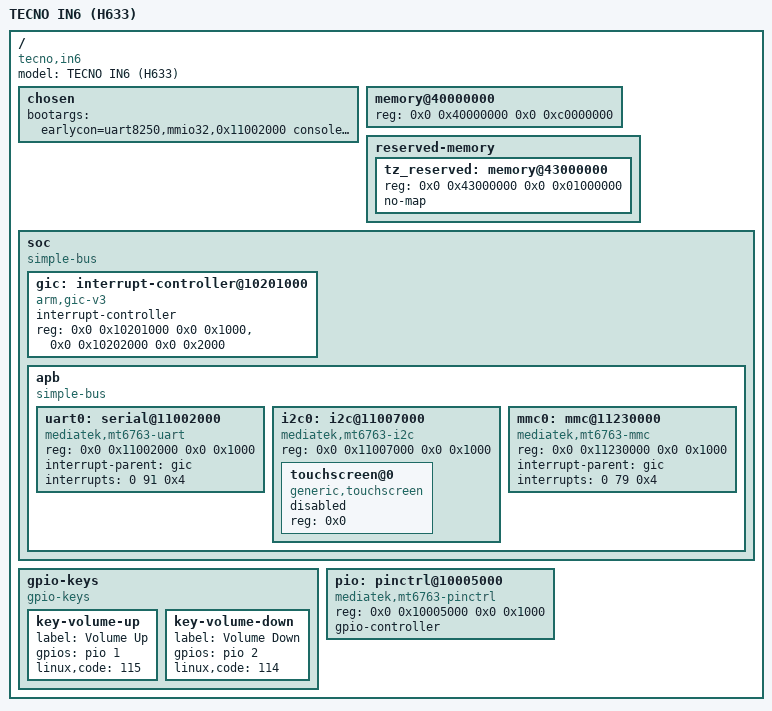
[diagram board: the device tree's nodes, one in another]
// SPDX-License-Identifier: GPL-2.0-only
/*
 * Device Tree Include for TECNO IN6 / H633 (MediaTek MT6763 / Helio P23)
 *
 * Copyright (c) 2025 IN6-Linux Project
 *
 * EVIDENCE TAGGING LEGEND:
 * - CONFIRMED FROM DEVICE: Verified via stock dumps (/proc/cpuinfo, /proc/bus/input/devices, getprop)
 * - CONFIRMED FROM DRIVER: Verified via driver subsystem files or config flags (tran_in6)
 * - INFERRED FROM MT6763: Deduced from standard MT6763 SoC register memory maps
 * - PLACEHOLDER / UNKNOWN: Value unmeasured; requires physical bus measurement or log dump
 */

/dts-v1/;

/ {
	/* CONFIRMED FROM DEVICE */
	compatible = "tecno,in6", "mediatek,mt6763";
	model = "TECNO IN6 (H633)";

	#address-cells = <2>;
	#size-cells = <2>;

	/* CONFIRMED FROM DRIVER: Boot command line arguments for earlycon serial console */
	chosen {
		bootargs = "earlycon=uart8250,mmio32,0x11002000 console=ttyS0,115200n8 root=/dev/mmcblk0p33 rw rootwait init=/init";
	};

	/* CONFIRMED FROM DEVICE: 3GB LPDDR memory mapping */
	memory@40000000 {
		device_type = "memory";
		reg = <0x0 0x40000000 0x0 0xc0000000>;
	};

	/* INFERRED FROM MT6763: TrustZone & SPM Reserved Memory */
	reserved-memory {
		#address-cells = <2>;
		#size-cells = <2>;
		ranges;

		tz_reserved: memory@43000000 {
			reg = <0x0 0x43000000 0x0 0x01000000>;
			no-map;
		};
	};

	soc {
		#address-cells = <2>;
		#size-cells = <2>;
		compatible = "simple-bus";
		ranges;

		/* INFERRED FROM MT6763: GIC-v3 Interrupt Controller */
		gic: interrupt-controller@10201000 {
			compatible = "arm,gic-v3";
			#interrupt-cells = <3>;
			interrupt-controller;
			reg = <0x0 0x10201000 0x0 0x1000>,
			      <0x0 0x10202000 0x0 0x2000>;
		};

		/* APB Bus Peripherals */
		apb {
			#address-cells = <2>;
			#size-cells = <2>;
			compatible = "simple-bus";
			ranges;

			/* CONFIRMED FROM DRIVER: UART0 console controller at 0x11002000 */
			uart0: serial@11002000 {
				compatible = "mediatek,mt6763-uart", "mediatek,mt6577-uart";
				reg = <0x0 0x11002000 0x0 0x1000>;
				interrupt-parent = <&gic>;
				interrupts = <0 91 0x4>;
				status = "okay";
			};

			/* INFERRED FROM MT6763: I2C Controller 0 */
			i2c0: i2c@11007000 {
				compatible = "mediatek,mt6763-i2c", "mediatek,mt6577-i2c";
				reg = <0x0 0x11007000 0x0 0x1000>;
				#address-cells = <1>;
				#size-cells = <0>;
				status = "okay";

				/* PLACEHOLDER / UNKNOWN: Touchscreen controller I2C slave address unmeasured */
				touchscreen@0 {
					compatible = "generic,touchscreen", "REQUIRES_IN6_MEASUREMENT";
					reg = <0x0>;
					status = "disabled";
				};
			};

			/* CONFIRMED FROM DEVICE: eMMC Host Controller mmc0 (/dev/block/mmcblk0) */
			mmc0: mmc@11230000 {
				compatible = "mediatek,mt6763-mmc", "mediatek,mt8173-mmc";
				reg = <0x0 0x11230000 0x0 0x1000>;
				interrupt-parent = <&gic>;
				interrupts = <0 79 0x4>;
				status = "okay";
			};
		};
	};

	/* CONFIRMED FROM DEVICE: Keypad event drivers (mtk-kpd & pmic_keys) */
	gpio-keys {
		compatible = "gpio-keys";

		key-volume-up {
			label = "Volume Up";
			gpios = <&pio 1 0>; /* INFERRED FROM MT6763: Placeholder pin assignment */
			linux,code = <115>; /* KEY_VOLUMEUP */
		};

		key-volume-down {
			label = "Volume Down";
			gpios = <&pio 2 0>; /* INFERRED FROM MT6763: Placeholder pin assignment */
			linux,code = <114>; /* KEY_VOLUMEDOWN */
		};
	};

	/* INFERRED FROM MT6763: MT6763 Pinctrl & GPIO Controller */
	pio: pinctrl@10005000 {
		compatible = "mediatek,mt6763-pinctrl";
		reg = <0x0 0x10005000 0x0 0x1000>;
		gpio-controller;
		#gpio-cells = <2>;
	};
};
